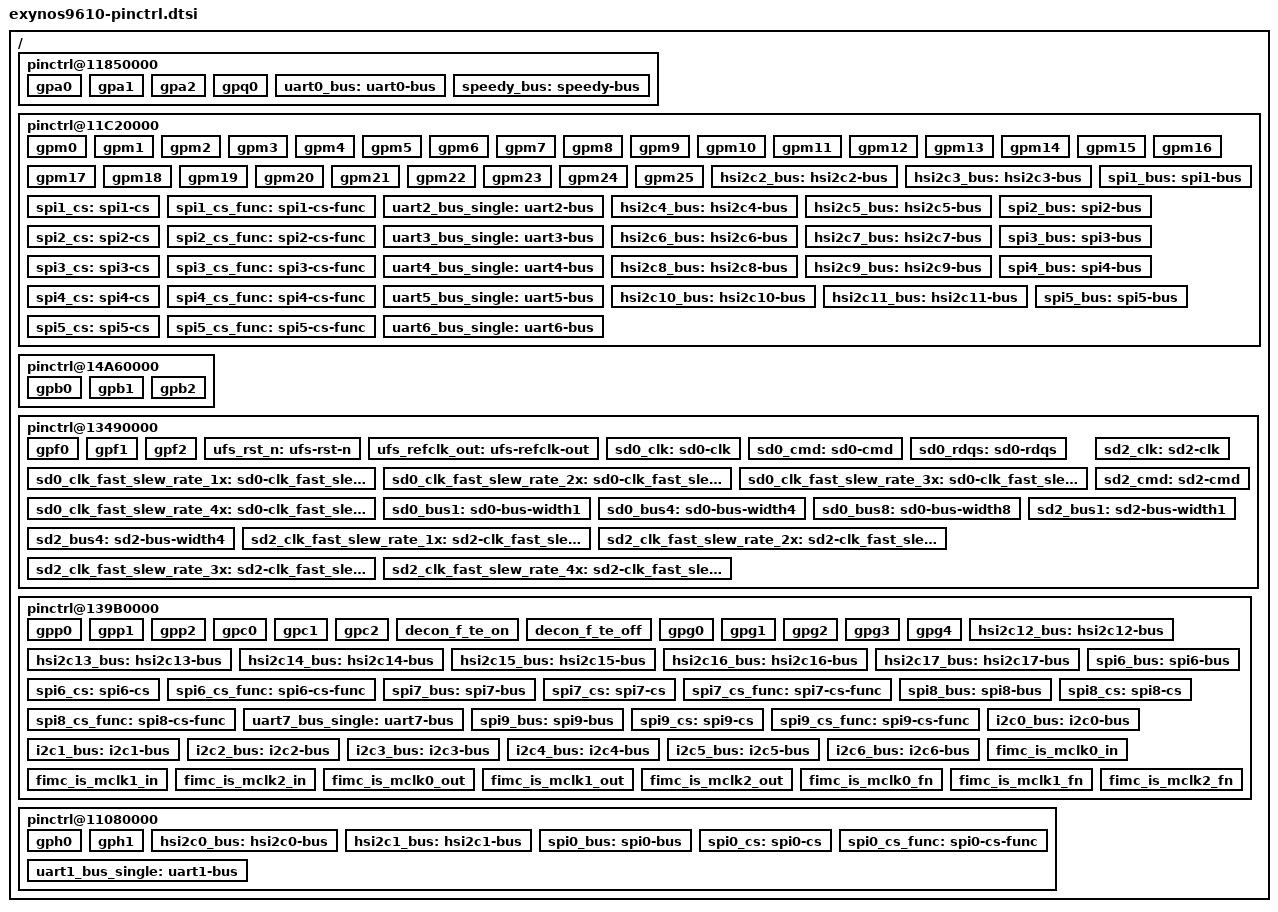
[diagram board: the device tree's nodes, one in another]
/*
 * Samsung's Exynos9610 SoC pin-mux and pin-config device tree source
 *
 * Copyright (c) 2017 Samsung Electronics Co., Ltd.
 *		http://www.samsung.com
 *
 * Samsung's Exynos9610 SoC pin-mux and pin-config options are listed as device
 * tree nodes are listed in this file.
 *
 * This program is free software; you can redistribute it and/or modify
 * it under the terms of the GNU General Public License version 2 as
 * published by the Free Software Foundation.
 */

/ {
	/* ALIVE */
	pinctrl@11850000 {
		gpa0: gpa0 {
			gpio-controller;
			#gpio-cells = <2>;

			interrupt-controller;
			#interrupt-cells = <3>;
			interrupt-parent = <&gic>;
			interrupts = <0 0 0>, <0 1 0>, <0 2 0>, <0 3 0>,
				     <0 4 0>, <0 5 0>, <0 6 0>, <0 7 0>;
		};

		gpa1: gpa1 {
			gpio-controller;
			#gpio-cells = <2>;

			interrupt-controller;
			#interrupt-cells = <3>;
			interrupt-parent = <&gic>;
			interrupts = <0 8 0>, <0 9 0>, <0 10 0>, <0 11 0>,
				     <0 12 0>, <0 13 0>, <0 14 0>, <0 15 0>;
		};

		gpa2: gpa2 {
			gpio-controller;
			#gpio-cells = <2>;

			interrupt-controller;
			#interrupt-cells = <3>;
			interrupt-parent = <&gic>;
			interrupts = <0 16 0>, <0 17 0>, <0 18 0>, <0 19 0>,
				     <0 20 0>, <0 21 0>, <0 22 0>, <0 23 0>;
		};

		gpq0: gpq0 {
			gpio-controller;
			#gpio-cells = <2>;

			interrupt-controller;
			#interrupt-cells = <2>;
		};

		/* USI_PERIC0_UART_DBG */
		uart0_bus: uart0-bus {
			samsung,pins = "gpq0-3", "gpq0-4";
			samsung,pin-function = <2>;
			samsung,pin-pud = <0>;
		};

		speedy_bus: speedy-bus {
			samsung,pins = "gpq0-2";
			samsung,pin-function = <2>;
			samsung,pin-pud = <3>;
			samsung,pin-drv = <0>;
		};
	};

	/* CMGP */
	pinctrl@11C20000{
		gpm0: gpm0 {
			gpio-controller;
			#gpio-cells = <2>;

			interrupt-controller;
			#interrupt-cells = <3>;
			interrupt-parent = <&gic>;
			interrupts = <0 142 0>;
		};

		gpm1: gpm1 {
			gpio-controller;
			#gpio-cells = <2>;

			interrupt-controller;
			#interrupt-cells = <3>;
			interrupt-parent = <&gic>;
			interrupts = <0 143 0>;
		};

		gpm2: gpm2 {
			gpio-controller;
			#gpio-cells = <2>;

			interrupt-controller;
			#interrupt-cells = <3>;
			interrupt-parent = <&gic>;
			interrupts = <0 144 0>;
		};

		gpm3: gpm3 {
			gpio-controller;
			#gpio-cells = <2>;

			interrupt-controller;
			#interrupt-cells = <3>;
			interrupt-parent = <&gic>;
			interrupts = <0 145 0>;
		};

		gpm4: gpm4 {
			gpio-controller;
			#gpio-cells = <2>;

			interrupt-controller;
			#interrupt-cells = <3>;
			interrupt-parent = <&gic>;
			interrupts = <0 158 0>;
		};

		gpm5: gpm5 {
			gpio-controller;
			#gpio-cells = <2>;

			interrupt-controller;
			#interrupt-cells = <3>;
			interrupt-parent = <&gic>;
			interrupts = <0 159 0>;
		};

		gpm6: gpm6 {
			gpio-controller;
			#gpio-cells = <2>;

			interrupt-controller;
			#interrupt-cells = <3>;
			interrupt-parent = <&gic>;
			interrupts = <0 160 0>;
		};

		gpm7: gpm7 {
			gpio-controller;
			#gpio-cells = <2>;

			interrupt-controller;
			#interrupt-cells = <3>;
			interrupt-parent = <&gic>;
			interrupts = <0 161 0>;
		};

		gpm8: gpm8 {
			gpio-controller;
			#gpio-cells = <2>;

			interrupt-controller;
			#interrupt-cells = <3>;
			interrupt-parent = <&gic>;
			interrupts = <0 162 0>;
		};

		gpm9: gpm9 {
			gpio-controller;
			#gpio-cells = <2>;

			interrupt-controller;
			#interrupt-cells = <3>;
			interrupt-parent = <&gic>;
			interrupts = <0 170 0>;
		};

		gpm10: gpm10 {
			gpio-controller;
			#gpio-cells = <2>;

			interrupt-controller;
			#interrupt-cells = <3>;
			interrupt-parent = <&gic>;
			interrupts = <0 171 0>;
		};

		gpm11: gpm11 {
			gpio-controller;
			#gpio-cells = <2>;

			interrupt-controller;
			#interrupt-cells = <3>;
			interrupt-parent = <&gic>;
			interrupts = <0 172 0>;
		};

		gpm12: gpm12 {
			gpio-controller;
			#gpio-cells = <2>;

			interrupt-controller;
			#interrupt-cells = <3>;
			interrupt-parent = <&gic>;
			interrupts = <0 173 0>;
		};

		gpm13: gpm13 {
			gpio-controller;
			#gpio-cells = <2>;

			interrupt-controller;
			#interrupt-cells = <3>;
			interrupt-parent = <&gic>;
			interrupts = <0 174 0>;
		};

		gpm14: gpm14 {
			gpio-controller;
			#gpio-cells = <2>;

			interrupt-controller;
			#interrupt-cells = <3>;
			interrupt-parent = <&gic>;
			interrupts = <0 185 0>;
		};

		gpm15: gpm15 {
			gpio-controller;
			#gpio-cells = <2>;

			interrupt-controller;
			#interrupt-cells = <3>;
			interrupt-parent = <&gic>;
			interrupts = <0 196 0>;
		};

		gpm16: gpm16 {
			gpio-controller;
			#gpio-cells = <2>;

			interrupt-controller;
			#interrupt-cells = <3>;
			interrupt-parent = <&gic>;
			interrupts = <0 197 0>;
		};

		gpm17: gpm17 {
			gpio-controller;
			#gpio-cells = <2>;

			interrupt-controller;
			#interrupt-cells = <3>;
			interrupt-parent = <&gic>;
			interrupts = <0 226 0>;
		};
		gpm18: gpm18 {
			gpio-controller;
			#gpio-cells = <2>;

			interrupt-controller;
			#interrupt-cells = <3>;
			interrupt-parent = <&gic>;
			interrupts = <0 227 0>;
		};

		gpm19: gpm19 {
			gpio-controller;
			#gpio-cells = <2>;

			interrupt-controller;
			#interrupt-cells = <3>;
			interrupt-parent = <&gic>;
			interrupts = <0 228 0>;
		};

		gpm20: gpm20 {
			gpio-controller;
			#gpio-cells = <2>;

			interrupt-controller;
			#interrupt-cells = <3>;
			interrupt-parent = <&gic>;
			interrupts = <0 269 0>;
		};

		gpm21: gpm21 {
			gpio-controller;
			#gpio-cells = <2>;

			interrupt-controller;
			#interrupt-cells = <3>;
			interrupt-parent = <&gic>;
			interrupts = <0 270 0>;
		};

		gpm22: gpm22 {
			gpio-controller;
			#gpio-cells = <2>;

			interrupt-controller;
			#interrupt-cells = <3>;
			interrupt-parent = <&gic>;
			interrupts = <0 272 0>;
		};

		gpm23: gpm23 {
			gpio-controller;
			#gpio-cells = <2>;

			interrupt-controller;
			#interrupt-cells = <3>;
			interrupt-parent = <&gic>;
			interrupts = <0 278 0>;
		};

		gpm24: gpm24 {
			gpio-controller;
			#gpio-cells = <2>;

			interrupt-controller;
			#interrupt-cells = <3>;
			interrupt-parent = <&gic>;
			interrupts = <0 318 0>;
		};

		gpm25: gpm25 {
			gpio-controller;
			#gpio-cells = <2>;

			interrupt-controller;
			#interrupt-cells = <3>;
			interrupt-parent = <&gic>;
			interrupts = <0 319 0>;
		};

		/* USI_0_CMGP */
		hsi2c2_bus: hsi2c2-bus {
			samsung,pins = "gpm0-0", "gpm1-0";
			samsung,pin-function = <2>;
			samsung,pin-pud = <0>;
			samsung,pin-drv = <0>;
		};

		/* USI_0_CMGP_I2C */
		hsi2c3_bus: hsi2c3-bus {
			samsung,pins = "gpm2-0", "gpm3-0";
			samsung,pin-function = <3>;
			samsung,pin-pud = <0>;
			samsung,pin-drv = <0>;
		};

		/* USI_0_CMGP */
		spi1_bus: spi1-bus {
			samsung,pins = "gpm0-0", "gpm1-0", "gpm2-0";
			samsung,pin-function = <2>;
			samsung,pin-pud = <0>;
			samsung,pin-drv = <0>;
		};

		spi1_cs: spi1-cs {
			samsung,pins = "gpm3-0";
			samsung,pin-function = <1>;
			samsung,pin-pud = <0>;
			samsung,pin-drv = <0>;
		};

		spi1_cs_func: spi1-cs-func {
			samsung,pins = "gpm3-0";
			samsung,pin-function = <2>;
			samsung,pin-pud = <0>;
			samsung,pin-drv = <0>;
		};

		/* USI_0_CMGP */
		uart2_bus_single: uart2-bus {
			samsung,pins = "gpm0-0", "gpm1-0", "gpm2-0", "gpm3-0";
			samsung,pin-function = <2>;
			samsung,pin-pud = <0>;
		};

		/* USI_1_CMGP */
		hsi2c4_bus: hsi2c4-bus {
			samsung,pins = "gpm4-0", "gpm5-0";
			samsung,pin-function = <2>;
			samsung,pin-pud = <0>;
			samsung,pin-drv = <0>;
		};

		/* USI_1_CMGP_I2C */
		hsi2c5_bus: hsi2c5-bus {
			samsung,pins = "gpm6-0", "gpm7-0";
			samsung,pin-function = <3>;
			samsung,pin-pud = <0>;
			samsung,pin-drv = <0>;
		};

		/* USI_1_CMGP */
		spi2_bus: spi2-bus {
			samsung,pins = "gpm4-0", "gpm5-0", "gpm6-0";
			samsung,pin-function = <2>;
			samsung,pin-pud = <0>;
			samsung,pin-drv = <0>;
		};

		spi2_cs: spi2-cs {
			samsung,pins = "gpm7-0";
			samsung,pin-function = <1>;
			samsung,pin-pud = <0>;
			samsung,pin-drv = <0>;
		};

		spi2_cs_func: spi2-cs-func {
			samsung,pins = "gpm7-0";
			samsung,pin-function = <2>;
			samsung,pin-pud = <0>;
			samsung,pin-drv = <0>;
		};

		/* USI_1_CMGP */
		uart3_bus_single: uart3-bus {
			samsung,pins = "gpm4-0", "gpm5-0", "gpm6-0", "gpm7-0";
			samsung,pin-function = <2>;
			samsung,pin-pud = <0>;
		};

		/* USI_2_CMGP */
		hsi2c6_bus: hsi2c6-bus {
			samsung,pins = "gpm8-0", "gpm9-0";
			samsung,pin-function = <2>;
			samsung,pin-pud = <0>;
			samsung,pin-drv = <0>;
		};

		/* USI_2_CMGP_I2C */
		hsi2c7_bus: hsi2c7-bus {
			samsung,pins = "gpm10-0", "gpm11-0";
			samsung,pin-function = <3>;
			samsung,pin-pud = <0>;
			samsung,pin-drv = <0>;
		};

		/* USI_2_CMGP */
		spi3_bus: spi3-bus {
			samsung,pins = "gpm8-0", "gpm9-0", "gpm10-0";
			samsung,pin-function = <2>;
			samsung,pin-pud = <0>;
			samsung,pin-drv = <0>;
		};

		spi3_cs: spi3-cs {
			samsung,pins = "gpm11-0";
			samsung,pin-function = <1>;
			samsung,pin-pud = <0>;
			samsung,pin-drv = <0>;
		};

		spi3_cs_func: spi3-cs-func {
			samsung,pins = "gpm11-0";
			samsung,pin-function = <2>;
			samsung,pin-pud = <0>;
			samsung,pin-drv = <0>;
		};

		/* USI_2_CMGP */
		uart4_bus_single: uart4-bus {
			samsung,pins = "gpm8-0", "gpm9-0", "gpm10-0", "gpm11-0";
			samsung,pin-function = <2>;
			samsung,pin-pud = <0>;
		};

		/* USI_3_CMGP */
		hsi2c8_bus: hsi2c8-bus {
			samsung,pins = "gpm12-0", "gpm13-0";
			samsung,pin-function = <2>;
			samsung,pin-pud = <0>;
			samsung,pin-drv = <0>;
		};

		/* USI_3_CMGP_I2C */
		hsi2c9_bus: hsi2c9-bus {
			samsung,pins = "gpm14-0", "gpm15-0";
			samsung,pin-function = <3>;
			samsung,pin-pud = <0>;
			samsung,pin-drv = <0>;
		};

		/* USI_3_CMGP */
		spi4_bus: spi4-bus {
			samsung,pins = "gpm12-0", "gpm13-0", "gpm14-0";
			samsung,pin-function = <2>;
			samsung,pin-pud = <0>;
			samsung,pin-drv = <0>;
		};

		spi4_cs: spi4-cs {
			samsung,pins = "gpm15-0";
			samsung,pin-function = <1>;
			samsung,pin-pud = <0>;
			samsung,pin-drv = <0>;
		};

		spi4_cs_func: spi4-cs-func {
			samsung,pins = "gpm15-0";
			samsung,pin-function = <2>;
			samsung,pin-pud = <0>;
			samsung,pin-drv = <0>;
		};

		/* USI_3_CMGP */
		uart5_bus_single: uart5-bus {
			samsung,pins = "gpm12-0", "gpm13-0", "gpm14-0", "gpm15-0";
			samsung,pin-function = <2>;
			samsung,pin-pud = <0>;
		};

		/* USI_4_CMGP */
		hsi2c10_bus: hsi2c10-bus {
			samsung,pins = "gpm16-0", "gpm17-0";
			samsung,pin-function = <2>;
			samsung,pin-pud = <0>;
			samsung,pin-drv = <0>;
		};

		/* USI_4_CMGP_I2C */
		hsi2c11_bus: hsi2c11-bus {
			samsung,pins = "gpm18-0", "gpm19-0";
			samsung,pin-function = <3>;
			samsung,pin-pud = <0>;
			samsung,pin-drv = <0>;
		};

		/* USI_4_CMGP */
		spi5_bus: spi5-bus {
			samsung,pins = "gpm16-0", "gpm17-0", "gpm18-0";
			samsung,pin-function = <2>;
			samsung,pin-pud = <0>;
			samsung,pin-drv = <0>;
		};

		spi5_cs: spi5-cs {
			samsung,pins = "gpm19-0";
			samsung,pin-function = <1>;
			samsung,pin-pud = <0>;
			samsung,pin-drv = <0>;
		};

		spi5_cs_func: spi5-cs-func {
			samsung,pins = "gpm19-0";
			samsung,pin-function = <2>;
			samsung,pin-pud = <0>;
			samsung,pin-drv = <0>;
		};

		/* USI_4_CMGP */
		uart6_bus_single: uart6-bus {
			samsung,pins = "gpm16-0", "gpm17-0", "gpm18-0", "gpm19-0";
			samsung,pin-function = <2>;
			samsung,pin-pud = <0>;
		};

	};

	/* DISPAUD */
	pinctrl@14A60000{
		gpb0: gpb0 {
			gpio-controller;
			#gpio-cells = <2>;

			interrupt-controller;
			#interrupt-cells = <2>;
		};

		gpb1: gpb1 {
			gpio-controller;
			#gpio-cells = <2>;

			interrupt-controller;
			#interrupt-cells = <2>;
		};

		gpb2: gpb2 {
			gpio-controller;
			#gpio-cells = <2>;

			interrupt-controller;
			#interrupt-cells = <2>;
		};
	};

	/* FSYS */
	pinctrl@13490000 {
		gpf0: gpf0 {
			gpio-controller;
			#gpio-cells = <2>;

			interrupt-controller;
			#interrupt-cells = <2>;
		};
		gpf1: gpf1 {
			gpio-controller;
			#gpio-cells = <2>;

			interrupt-controller;
			#interrupt-cells = <2>;
		};
		gpf2: gpf2 {
			gpio-controller;
			#gpio-cells = <2>;

			interrupt-controller;
			#interrupt-cells = <2>;
		};

		ufs_rst_n: ufs-rst-n {
			samsung,pins = "gpf0-1";
			samsung,pin-function = <3>;
			samsung,pin-pud = <0>;
			samsung,pin-con-pdn = <3>;
		};

		ufs_refclk_out: ufs-refclk-out {
			samsung,pins = "gpf0-0";
			samsung,pin-function = <3>;
			samsung,pin-pud = <0>;
			samsung,pin-con-pdn = <3>;
		};

		sd0_clk: sd0-clk {
			samsung,pins = "gpf0-0";
			samsung,pin-function = <2>;
			samsung,pin-pud = <0>;
			samsung,pin-drv = <3>;
		};

		sd0_cmd: sd0-cmd {
			samsung,pins = "gpf0-1";
			samsung,pin-function = <2>;
			samsung,pin-pud = <3>;
			samsung,pin-drv = <3>;
		};

		sd0_rdqs: sd0-rdqs {
			samsung,pins = "gpf0-2";
			samsung,pin-function = <2>;
			samsung,pin-pud = <1>;
			samsung,pin-drv = <3>;
		};

		sd0_clk_fast_slew_rate_1x: sd0-clk_fast_slew_rate_1x {
			samsung,pins = "gpf0-0";
			samsung,pin-function = <2>;
			samsung,pin-pud = <0>;
			samsung,pin-drv = <0>;
		};

		sd0_clk_fast_slew_rate_2x: sd0-clk_fast_slew_rate_2x {
			samsung,pins = "gpf0-0";
			samsung,pin-function = <2>;
			samsung,pin-pud = <0>;
			samsung,pin-drv = <1>;
		};

		sd0_clk_fast_slew_rate_3x: sd0-clk_fast_slew_rate_3x {
			samsung,pins = "gpf0-0";
			samsung,pin-function = <2>;
			samsung,pin-pud = <0>;
			samsung,pin-drv = <2>;
		};

		sd0_clk_fast_slew_rate_4x: sd0-clk_fast_slew_rate_4x {
			samsung,pins = "gpf0-0";
			samsung,pin-function = <2>;
			samsung,pin-pud = <0>;
			samsung,pin-drv = <3>;
		};

		sd0_bus1: sd0-bus-width1 {
			samsung,pins = "gpf1-0";
			samsung,pin-function = <2>;
			samsung,pin-pud = <3>;
			samsung,pin-drv = <3>;
		};

		sd0_bus4: sd0-bus-width4 {
			samsung,pins = "gpf1-1", "gpf1-2", "gpf1-3";
			samsung,pin-function = <2>;
			samsung,pin-pud = <3>;
			samsung,pin-drv = <3>;
		};

		sd0_bus8: sd0-bus-width8 {
			samsung,pins = "gpf1-4", "gpf1-5", "gpf1-6", "gpf1-7";
			samsung,pin-function = <2>;
			samsung,pin-pud = <3>;
			samsung,pin-drv = <3>;
		};

		sd2_clk: sd2-clk {
			samsung,pins = "gpf2-0";
			samsung,pin-function = <2>;
			samsung,pin-pud = <0>;
			samsung,pin-drv = <2>;
		};

		sd2_cmd: sd2-cmd {
			samsung,pins = "gpf2-1";
			samsung,pin-function = <2>;
			samsung,pin-pud = <3>;
			samsung,pin-drv = <2>;
		};

		sd2_bus1: sd2-bus-width1 {
			samsung,pins = "gpf2-2";
			samsung,pin-function = <2>;
			samsung,pin-pud = <3>;
			samsung,pin-drv = <2>;
		};

		sd2_bus4: sd2-bus-width4 {
			samsung,pins = "gpf2-3", "gpf2-4", "gpf2-5";
			samsung,pin-function = <2>;
			samsung,pin-pud = <3>;
			samsung,pin-drv = <2>;
		};

		sd2_clk_fast_slew_rate_1x: sd2-clk_fast_slew_rate_1x {
			samsung,pins = "gpf2-0";
			samsung,pin-function = <2>;
			samsung,pin-pud = <0>;
			samsung,pin-drv = <0>;
		};

		sd2_clk_fast_slew_rate_2x: sd2-clk_fast_slew_rate_2x {
			samsung,pins = "gpf2-0";
			samsung,pin-function = <2>;
			samsung,pin-pud = <0>;
			samsung,pin-drv = <1>;
		};

		sd2_clk_fast_slew_rate_3x: sd2-clk_fast_slew_rate_3x {
			samsung,pins = "gpf2-0";
			samsung,pin-function = <2>;
			samsung,pin-pud = <0>;
			samsung,pin-drv = <2>;
		};

		sd2_clk_fast_slew_rate_4x: sd2-clk_fast_slew_rate_4x {
			samsung,pins = "gpf2-0";
			samsung,pin-function = <2>;
			samsung,pin-pud = <0>;
			samsung,pin-drv = <3>;
		};
	};

	/* TOP */
	pinctrl@139B0000 {
		gpp0: gpp0 {
			gpio-controller;
			#gpio-cells = <2>;

			interrupt-controller;
			#interrupt-cells = <2>;
		};

		gpp1: gpp1 {
			gpio-controller;
			#gpio-cells = <2>;

			interrupt-controller;
			#interrupt-cells = <2>;
		};

		gpp2: gpp2 {
			gpio-controller;
			#gpio-cells = <2>;

			interrupt-controller;
			#interrupt-cells = <2>;
		};

		gpc0: gpc0 {
			gpio-controller;
			#gpio-cells = <2>;

			interrupt-controller;
			#interrupt-cells = <2>;
		};

		gpc1: gpc1 {
			gpio-controller;
			#gpio-cells = <2>;

			interrupt-controller;
			#interrupt-cells = <2>;
		};

		gpc2: gpc2 {
			gpio-controller;
			#gpio-cells = <2>;

			interrupt-controller;
			#interrupt-cells = <2>;
		};

		decon_f_te_on: decon_f_te_on {
			samsung,pins = "gpc2-3";
			samsung,pin-function = <0xf>;
		};

		decon_f_te_off: decon_f_te_off {
			samsung,pins = "gpc2-3";
			samsung,pin-function = <0>;
		};

		gpg0: gpg0 {
			gpio-controller;
			#gpio-cells = <2>;

			interrupt-controller;
			#interrupt-cells = <2>;
		};

		gpg1: gpg1 {
			gpio-controller;
			#gpio-cells = <2>;

			interrupt-controller;
			#interrupt-cells = <2>;
		};

		gpg2: gpg2 {
			gpio-controller;
			#gpio-cells = <2>;

			interrupt-controller;
			#interrupt-cells = <2>;
		};

		gpg3: gpg3 {
			gpio-controller;
			#gpio-cells = <2>;

			interrupt-controller;
			#interrupt-cells = <2>;
		};

		gpg4: gpg4 {
			gpio-controller;
			#gpio-cells = <2>;

			interrupt-controller;
			#interrupt-cells = <2>;
		};

		/* USI_PERI_CAMI2C_0 */
		hsi2c12_bus: hsi2c12-bus {
			samsung,pins = "gpc0-0", "gpc0-1";
			samsung,pin-function = <2>;
			samsung,pin-pud = <0>;
			samsung,pin-drv = <0>;
		};

		/* USI_PERI_CAMI2C_1 */
		hsi2c13_bus: hsi2c13-bus {
			samsung,pins = "gpc0-2", "gpc0-3";
			samsung,pin-function = <2>;
			samsung,pin-pud = <0>;
			samsung,pin-drv = <0>;
		};

		/* USI_PERI_CAMI2C_2 */
		hsi2c14_bus: hsi2c14-bus {
			samsung,pins = "gpc0-4", "gpc0-5";
			samsung,pin-function = <2>;
			samsung,pin-pud = <3>;
			samsung,pin-drv = <0>;
		};

		/* USI_PERI_CAMI2C_3 */
		hsi2c15_bus: hsi2c15-bus {
			samsung,pins = "gpc0-6", "gpc0-7";
			samsung,pin-function = <2>;
			samsung,pin-pud = <0>;
			samsung,pin-drv = <0>;
		};

		/* USI_PERI_USI_0 */
		hsi2c16_bus: hsi2c16-bus {
			samsung,pins = "gpc1-0", "gpc1-1";
			samsung,pin-function = <2>;
			samsung,pin-pud = <0>;
			samsung,pin-drv = <0>;
		};

		/* USI_PERI_USI_0_I2C */
		hsi2c17_bus: hsi2c17-bus {
			samsung,pins = "gpc1-2", "gpc1-3";
			samsung,pin-function = <3>;
			samsung,pin-pud = <0>;
			samsung,pin-drv = <0>;
		};

		/* USI_PERI_SPI_0  */
		spi6_bus: spi6-bus {
			samsung,pins = "gpp2-0", "gpp2-1", "gpp2-2";
			samsung,pin-function = <2>;
			samsung,pin-pud = <0>;
			samsung,pin-drv = <0>;
		};

		spi6_cs: spi6-cs {
			samsung,pins = "gpp2-3";
			samsung,pin-function = <1>;
			samsung,pin-pud = <0>;
			samsung,pin-drv = <0>;
		};

		spi6_cs_func: spi6-cs-func {
			samsung,pins = "gpp2-3";
			samsung,pin-function = <2>;
			samsung,pin-pud = <0>;
			samsung,pin-drv = <0>;
		};

		/* USI_PERI_SPI_1  */
		spi7_bus: spi7-bus {
			samsung,pins = "gpp2-4", "gpp2-5", "gpp2-6";
			samsung,pin-function = <2>;
			samsung,pin-pud = <0>;
			samsung,pin-drv = <0>;
		};

		spi7_cs: spi7-cs {
			samsung,pins = "gpp2-7";
			samsung,pin-function = <1>;
			samsung,pin-pud = <0>;
			samsung,pin-drv = <0>;
		};

		spi7_cs_func: spi7-cs-func {
			samsung,pins = "gpp2-7";
			samsung,pin-function = <2>;
			samsung,pin-pud = <0>;
			samsung,pin-drv = <0>;
		};

		/* USI_PERI_USI_0 */
		spi8_bus: spi8-bus {
			samsung,pins = "gpc1-0", "gpc1-1", "gpc1-2";
			samsung,pin-function = <2>;
			samsung,pin-pud = <0>;
			samsung,pin-drv = <0>;
		};

		spi8_cs: spi8-cs {
			samsung,pins = "gpc1-3";
			samsung,pin-function = <1>;
			samsung,pin-pud = <0>;
			samsung,pin-drv = <0>;
		};

		spi8_cs_func: spi8-cs-func {
			samsung,pins = "gpc1-3";
			samsung,pin-function = <2>;
			samsung,pin-pud = <0>;
			samsung,pin-drv = <0>;
		};

		/* USI_PERI_USI_0 */
		uart7_bus_single: uart7-bus {
			samsung,pins = "gpc1-0", "gpc1-1", "gpc1-2", "gpc1-3";
			samsung,pin-function = <2>;
			samsung,pin-pud = <0>;
		};

		/* SPI USI_PERI_SPI_2 */
		spi9_bus: spi9-bus {
			samsung,pins = "gpc1-4", "gpc1-5", "gpc1-6";
			samsung,pin-function = <2>;
			samsung,pin-pud = <0>;
			samsung,pin-drv = <0>;
		};

		spi9_cs: spi9-cs {
			samsung,pins = "gpc1-7";
			samsung,pin-function = <1>;
			samsung,pin-pud = <0>;
			samsung,pin-drv = <0>;
		};

		spi9_cs_func: spi9-cs-func {
			samsung,pins = "gpc1-7";
			samsung,pin-function = <2>;
			samsung,pin-pud = <0>;
			samsung,pin-drv = <0>;
		};

		i2c0_bus: i2c0-bus {
			samsung,pins = "gpp0-1", "gpp0-0";
			samsung,pin-function = <2>;
			samsung,pin-pud = <0>;
			samsung,pin-drv = <0>;
		};

		i2c1_bus: i2c1-bus {
			samsung,pins = "gpp0-3", "gpp0-2";
			samsung,pin-function = <2>;
			samsung,pin-pud = <0>;
			samsung,pin-drv = <0>;
		};

		i2c2_bus: i2c2-bus {
			samsung,pins = "gpp0-5", "gpp0-4";
			samsung,pin-function = <2>;
			samsung,pin-pud = <0>;
			samsung,pin-drv = <0>;
		};

		i2c3_bus: i2c3-bus {
			samsung,pins = "gpp0-7", "gpp0-6";
			samsung,pin-function = <2>;
			samsung,pin-pud = <0>;
			samsung,pin-drv = <0>;
		};

		i2c4_bus: i2c4-bus {
			samsung,pins = "gpp1-1", "gpp1-0";
			samsung,pin-function = <2>;
			samsung,pin-pud = <0>;
			samsung,pin-drv = <0>;
		};

		i2c5_bus: i2c5-bus {
			samsung,pins = "gpp1-3", "gpp1-2";
			samsung,pin-function = <2>;
			samsung,pin-pud = <0>;
			samsung,pin-drv = <0>;
		};

		i2c6_bus: i2c6-bus {
			samsung,pins = "gpp1-5", "gpp1-4";
			samsung,pin-function = <2>;
			samsung,pin-pud = <0>;
			samsung,pin-drv = <0>;
		};

		fimc_is_mclk0_in: fimc_is_mclk0_in {
			samsung,pins = "gpc2-0";
			samsung,pin-function = <0>;
			samsung,pin-pud = <0>;
			samsung,pin-drv = <2>;
		};

		fimc_is_mclk1_in: fimc_is_mclk1_in {
			samsung,pins = "gpc2-1";
			samsung,pin-function = <0>;
			samsung,pin-pud = <0>;
			samsung,pin-drv = <2>;
		};

		fimc_is_mclk2_in: fimc_is_mclk2_in {
			samsung,pins = "gpc2-2";
			samsung,pin-function = <0>;
			samsung,pin-pud = <0>;
			samsung,pin-drv = <2>;
		};

		fimc_is_mclk0_out: fimc_is_mclk0_out {
			samsung,pins = "gpc2-0";
			samsung,pin-function = <1>;
			samsung,pin-pud = <1>;
			samsung,pin-drv = <2>;
		};

		fimc_is_mclk1_out: fimc_is_mclk1_out {
			samsung,pins = "gpc2-1";
			samsung,pin-function = <1>;
			samsung,pin-pud = <1>;
			samsung,pin-drv = <2>;
		};

		fimc_is_mclk2_out: fimc_is_mclk2_out {
			samsung,pins = "gpc2-2";
			samsung,pin-function = <1>;
			samsung,pin-pud = <1>;
			samsung,pin-drv = <2>;
		};

		fimc_is_mclk0_fn: fimc_is_mclk0_fn {
			samsung,pins = "gpc2-0";
			samsung,pin-function = <2>;
			samsung,pin-pud = <0>;
			samsung,pin-drv = <2>;
		};

		fimc_is_mclk1_fn: fimc_is_mclk1_fn {
			samsung,pins = "gpc2-1";
			samsung,pin-function = <2>;
			samsung,pin-pud = <0>;
			samsung,pin-drv = <2>;
		};

		fimc_is_mclk2_fn: fimc_is_mclk2_fn {
			samsung,pins = "gpc2-2";
			samsung,pin-function = <2>;
			samsung,pin-pud = <0>;
			samsung,pin-drv = <2>;
		};

	};

	/* SHUB */
	pinctrl@11080000{
		gph0: gph0 {
			gpio-controller;
			#gpio-cells = <2>;

			interrupt-controller;
			#interrupt-cells = <2>;
		};

		gph1: gph1 {
			gpio-controller;
			#gpio-cells = <2>;

			interrupt-controller;
			#interrupt-cells = <2>;
		};

		/* USI_0_SHUB */
		hsi2c0_bus: hsi2c0-bus {
			samsung,pins = "gph0-0", "gph0-1";
			samsung,pin-function = <2>;
			samsung,pin-pud = <0>;
			samsung,pin-drv = <0>;
		};

		/* USI_0_SHUB_I2C */
		hsi2c1_bus: hsi2c1-bus {
			samsung,pins = "gph0-2", "gph0-3";
			samsung,pin-function = <3>;
			samsung,pin-pud = <0>;
			samsung,pin-drv = <0>;
		};

		/* USI_0_SHUB */
		spi0_bus: spi0-bus {
			samsung,pins = "gph0-2", "gph0-1", "gph0-0";
			samsung,pin-function = <2>;
			samsung,pin-pud = <0>;
			samsung,pin-drv = <0>;
		};

		spi0_cs: spi0-cs {
			samsung,pins = "gph0-3";
			samsung,pin-function = <1>;
			samsung,pin-pud = <0>;
			samsung,pin-drv = <0>;
		};

		spi0_cs_func: spi0-cs-func {
			samsung,pins = "gph0-3";
			samsung,pin-function = <2>;
			samsung,pin-pud = <0>;
			samsung,pin-drv = <0>;
		};

		/* USI_0_SHUB */
		uart1_bus_single: uart1-bus {
			samsung,pins = "gph0-3", "gph0-2", "gph0-1", "gph0-0";
			samsung,pin-function = <2>;
			samsung,pin-pud = <0>;
		};

	};
};
